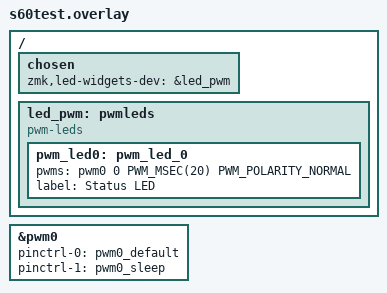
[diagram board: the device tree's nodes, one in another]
/*
 * Copyright (c) 2025 Team PHDesign
 *
 * SPDX-License-Identifier: MIT
 */

#include "s60test.dtsi"

/ {
	chosen {
		zmk,led-widgets-dev = &led_pwm;
	};

	led_pwm: pwmleds {
		compatible = "pwm-leds";
		status = "okay";
		
		pwm_led0: pwm_led_0 {
			pwms = <&pwm0 0 PWM_MSEC(20) PWM_POLARITY_NORMAL>;
			label = "Status LED";
		};
	};
};

&pwm0 {
	status = "okay";
	pinctrl-0 = <&pwm0_default>;
	pinctrl-1 = <&pwm0_sleep>;
	pinctrl-names = "default", "sleep";
};
